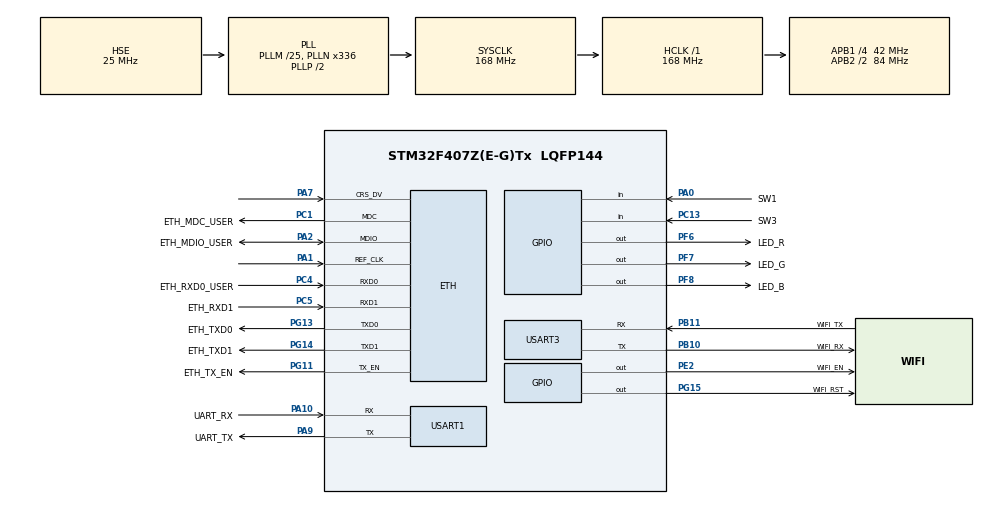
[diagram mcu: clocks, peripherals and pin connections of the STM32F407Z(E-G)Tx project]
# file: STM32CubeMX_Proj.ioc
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Dma.Request0=USART1_TX
Dma.Request1=USART1_RX
Dma.Request2=USART3_RX
Dma.Request3=USART3_TX
Dma.USART1_RX.1.Direction=DMA_PERIPH_TO_MEMORY
Dma.USART1_RX.1.FIFOMode=DMA_FIFOMODE_DISABLE
Dma.USART1_RX.1.Instance=DMA2_Stream2
Dma.USART1_RX.1.MemDataAlignment=DMA_MDATAALIGN_BYTE
Dma.USART1_RX.1.MemInc=DMA_MINC_ENABLE
Dma.USART1_RX.1.Mode=DMA_NORMAL
Dma.USART1_RX.1.PeriphDataAlignment=DMA_PDATAALIGN_BYTE
Dma.USART1_RX.1.PeriphInc=DMA_PINC_DISABLE
Dma.USART1_RX.1.Priority=DMA_PRIORITY_MEDIUM
Dma.USART1_TX.0.Direction=DMA_MEMORY_TO_PERIPH
Dma.USART1_TX.0.FIFOMode=DMA_FIFOMODE_DISABLE
Dma.USART1_TX.0.Instance=DMA2_Stream7
Dma.USART1_TX.0.MemDataAlignment=DMA_MDATAALIGN_BYTE
Dma.USART1_TX.0.MemInc=DMA_MINC_ENABLE
Dma.USART1_TX.0.Mode=DMA_NORMAL
Dma.USART1_TX.0.PeriphDataAlignment=DMA_PDATAALIGN_BYTE
Dma.USART1_TX.0.PeriphInc=DMA_PINC_DISABLE
Dma.USART1_TX.0.Priority=DMA_PRIORITY_MEDIUM
Dma.USART3_RX.2.Direction=DMA_PERIPH_TO_MEMORY
Dma.USART3_RX.2.FIFOMode=DMA_FIFOMODE_DISABLE
Dma.USART3_RX.2.Instance=DMA1_Stream1
Dma.USART3_RX.2.MemDataAlignment=DMA_MDATAALIGN_BYTE
Dma.USART3_RX.2.MemInc=DMA_MINC_ENABLE
Dma.USART3_RX.2.Mode=DMA_NORMAL
Dma.USART3_RX.2.PeriphDataAlignment=DMA_PDATAALIGN_BYTE
Dma.USART3_RX.2.PeriphInc=DMA_PINC_DISABLE
Dma.USART3_RX.2.Priority=DMA_PRIORITY_LOW
Dma.USART3_TX.3.Direction=DMA_MEMORY_TO_PERIPH
Dma.USART3_TX.3.FIFOMode=DMA_FIFOMODE_DISABLE
Dma.USART3_TX.3.Instance=DMA1_Stream3
Dma.USART3_TX.3.MemDataAlignment=DMA_MDATAALIGN_BYTE
Dma.USART3_TX.3.MemInc=DMA_MINC_ENABLE
Dma.USART3_TX.3.Mode=DMA_NORMAL
Dma.USART3_TX.3.PeriphDataAlignment=DMA_PDATAALIGN_BYTE
Dma.USART3_TX.3.PeriphInc=DMA_PINC_DISABLE
Dma.USART3_TX.3.Priority=DMA_PRIORITY_LOW
ETH.MediaInterface=HAL_ETH_RMII_MODE
Mcu.Family=STM32F4
Mcu.Name=STM32F407Z(E-G)Tx
Mcu.Package=LQFP144
NVIC.DMA1_Stream1_IRQn=true\:0\:0\:false\:false\:true\:false\:true\:true
NVIC.DMA1_Stream3_IRQn=true\:0\:0\:false\:false\:true\:false\:true\:true
NVIC.DMA2_Stream2_IRQn=true\:0\:0\:false\:false\:true\:false\:true\:true
NVIC.DMA2_Stream7_IRQn=true\:0\:0\:false\:false\:true\:false\:true\:true
NVIC.PriorityGroup=NVIC_PRIORITYGROUP_4
NVIC.USART1_IRQn=true\:0\:0\:false\:false\:true\:false\:true\:true
NVIC.USART3_IRQn=true\:0\:0\:false\:false\:true\:false\:true\:true
PA0-WKUP.GPIO_Label=SW1
PA0-WKUP.Signal=GPIO_Input
PA1.Mode=RMII
PA1.Signal=ETH_REF_CLK
PA10.GPIO_Label=UART_RX
PA10.Mode=Asynchronous
PA10.Signal=USART1_RX
PA2.GPIO_Label=ETH_MDIO_USER
PA2.Mode=RMII
PA2.Signal=ETH_MDIO
PA7.Mode=RMII
PA7.Signal=ETH_CRS_DV
PA9.GPIO_Label=UART_TX
PA9.Mode=Asynchronous
PA9.Signal=USART1_TX
PB10.GPIO_Label=WIFI_RX
PB10.Mode=Asynchronous
PB10.Signal=USART3_TX
PB11.GPIO_Label=WIFI_TX
PB11.Mode=Asynchronous
PB11.Signal=USART3_RX
PC1.GPIO_Label=ETH_MDC_USER
PC1.Mode=RMII
PC1.Signal=ETH_MDC
PC13-ANTI_TAMP.GPIO_Label=SW3
PC13-ANTI_TAMP.Signal=GPIO_Input
PC4.GPIO_Label=ETH_RXD0_USER
PC4.Mode=RMII
PC4.Signal=ETH_RXD0
PC5.GPIO_Label=ETH_RXD1
PC5.Mode=RMII
PC5.Signal=ETH_RXD1
PE2.GPIO_Label=WIFI_EN
PE2.PinState=GPIO_PIN_RESET
PE2.Signal=GPIO_Output
PF6.GPIO_Label=LED_R
PF6.PinState=GPIO_PIN_SET
PF6.Signal=GPIO_Output
PF7.GPIO_Label=LED_G
PF7.PinState=GPIO_PIN_SET
PF7.Signal=GPIO_Output
PF8.GPIO_Label=LED_B
PF8.PinState=GPIO_PIN_SET
PF8.Signal=GPIO_Output
PG11.GPIO_Label=ETH_TX_EN
PG11.Mode=RMII
PG11.Signal=ETH_TX_EN
PG13.GPIO_Label=ETH_TXD0
PG13.Mode=RMII
PG13.Signal=ETH_TXD0
PG14.GPIO_Label=ETH_TXD1
PG14.Mode=RMII
PG14.Signal=ETH_TXD1
PG15.GPIO_Label=WIFI_RST
PG15.Signal=GPIO_Output
PH0-OSC_IN.Mode=HSE-External-Oscillator
PH0-OSC_IN.Signal=RCC_OSC_IN
PH1-OSC_OUT.Mode=HSE-External-Oscillator
PH1-OSC_OUT.Signal=RCC_OSC_OUT
ProjectManager.HeapSize=0x200
ProjectManager.StackSize=0x400
ProjectManager.TargetToolchain=MDK-ARM V5.32
RCC.48MHZClocksFreq_Value=84000000
RCC.AHBFreq_Value=168000000
RCC.APB1CLKDivider=RCC_HCLK_DIV4
RCC.APB1Freq_Value=42000000
RCC.APB1TimFreq_Value=84000000
RCC.APB2CLKDivider=RCC_HCLK_DIV2
RCC.APB2Freq_Value=84000000
RCC.APB2TimFreq_Value=168000000
RCC.CortexFreq_Value=168000000
RCC.HCLKFreq_Value=168000000
RCC.HSE_VALUE=25000000
RCC.HSI_VALUE=16000000
RCC.LSE_VALUE=32768
RCC.PLLM=25
RCC.PLLN=336
RCC.PLLSourceVirtual=RCC_PLLSOURCE_HSE
RCC.SYSCLKFreq_VALUE=168000000
RCC.SYSCLKSource=RCC_SYSCLKSOURCE_PLLCLK
RCC.VCOOutputFreq_Value=336000000
USART1.VirtualMode=VM_ASYNC
USART3.VirtualMode=VM_ASYNC
board=custom

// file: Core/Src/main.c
/* USER CODE BEGIN Header */
/**
  ******************************************************************************
  * @file           : main.c
  * @brief          : Main program body
  ******************************************************************************
  * @attention
  *
  * Copyright (c) 2026 STMicroelectronics.
  * All rights reserved.
  *
  * This software is licensed under terms that can be found in the LICENSE file
  * in the root directory of this software component.
  * If no LICENSE file comes with this software, it is provided AS-IS.
  *
  ******************************************************************************
  */
/* USER CODE END Header */
#include "main.h"

//ETH_TxPacketConfig TxConfig;
//ETH_DMADescTypeDef  DMARxDscrTab[ETH_RX_DESC_CNT]; /* Ethernet Rx DMA Descriptors */
//ETH_DMADescTypeDef  DMATxDscrTab[ETH_TX_DESC_CNT]; /* Ethernet Tx DMA Descriptors */

//ETH_HandleTypeDef heth;

UART_HandleTypeDef huart1;
UART_HandleTypeDef huart3;
DMA_HandleTypeDef hdma_usart1_tx;
DMA_HandleTypeDef hdma_usart1_rx;
DMA_HandleTypeDef hdma_usart3_rx;
DMA_HandleTypeDef hdma_usart3_tx;

void SystemClock_Config(void);
static void MX_GPIO_Init(void);
static void MX_DMA_Init(void);
static void MX_USART1_UART_Init(void);
static void MX_USART3_UART_Init(void);
//static void MX_ETH_Init(void);

int main(void)
{

  /* MCU Configuration--------------------------------------------------------*/

  /* Reset of all peripherals, Initializes the Flash interface and the Systick. */
  HAL_Init();

  /* Configure the system clock */
  SystemClock_Config();

  /* Initialize all configured peripherals */
  MX_GPIO_Init();
  MX_DMA_Init();
  MX_USART1_UART_Init();
  MX_USART3_UART_Init();
	WIFI_Enable();
	printf("==> BSP初始化成功\n");
  /* USER CODE BEGIN 2 */
	User_Start_Tasks();
  /* USER CODE END 2 */

  /* Infinite loop */
  while (1)
  {

  }
}

void SystemClock_Config(void)
{
  RCC_OscInitTypeDef RCC_OscInitStruct = {0};
  RCC_ClkInitTypeDef RCC_ClkInitStruct = {0};

  /** Configure the main internal regulator output voltage
  */
  __HAL_RCC_PWR_CLK_ENABLE();
  __HAL_PWR_VOLTAGESCALING_CONFIG(PWR_REGULATOR_VOLTAGE_SCALE1);

  /** Initializes the RCC Oscillators according to the specified parameters
  * in the RCC_OscInitTypeDef structure.
  */
  RCC_OscInitStruct.OscillatorType = RCC_OSCILLATORTYPE_HSE;
  RCC_OscInitStruct.HSEState = RCC_HSE_ON;
  RCC_OscInitStruct.PLL.PLLState = RCC_PLL_ON;
  RCC_OscInitStruct.PLL.PLLSource = RCC_PLLSOURCE_HSE;
  RCC_OscInitStruct.PLL.PLLM = 25;
  RCC_OscInitStruct.PLL.PLLN = 336;
  RCC_OscInitStruct.PLL.PLLP = RCC_PLLP_DIV2;
  RCC_OscInitStruct.PLL.PLLQ = 4;
  if (HAL_RCC_OscConfig(&RCC_OscInitStruct) != HAL_OK)
  {
    Error_Handler();
  }

  /** Initializes the CPU, AHB and APB buses clocks
  */
  RCC_ClkInitStruct.ClockType = RCC_CLOCKTYPE_HCLK|RCC_CLOCKTYPE_SYSCLK
                              |RCC_CLOCKTYPE_PCLK1|RCC_CLOCKTYPE_PCLK2;
  RCC_ClkInitStruct.SYSCLKSource = RCC_SYSCLKSOURCE_PLLCLK;
  RCC_ClkInitStruct.AHBCLKDivider = RCC_SYSCLK_DIV1;
  RCC_ClkInitStruct.APB1CLKDivider = RCC_HCLK_DIV4;
  RCC_ClkInitStruct.APB2CLKDivider = RCC_HCLK_DIV2;

  if (HAL_RCC_ClockConfig(&RCC_ClkInitStruct, FLASH_LATENCY_5) != HAL_OK)
  {
    Error_Handler();
  }
}

static void MX_USART1_UART_Init(void)
{

  huart1.Instance = USART1;
  huart1.Init.BaudRate = 115200;
  huart1.Init.WordLength = UART_WORDLENGTH_8B;
  huart1.Init.StopBits = UART_STOPBITS_1;
  huart1.Init.Parity = UART_PARITY_NONE;
  huart1.Init.Mode = UART_MODE_TX_RX;
  huart1.Init.HwFlowCtl = UART_HWCONTROL_NONE;
  huart1.Init.OverSampling = UART_OVERSAMPLING_16;
  if (HAL_UART_Init(&huart1) != HAL_OK)
  {
    Error_Handler();
  }

}

static void MX_USART3_UART_Init(void)
{

  huart3.Instance = USART3;
  huart3.Init.BaudRate = 115200;
  huart3.Init.WordLength = UART_WORDLENGTH_8B;
  huart3.Init.StopBits = UART_STOPBITS_1;
  huart3.Init.Parity = UART_PARITY_NONE;
  huart3.Init.Mode = UART_MODE_TX_RX;
  huart3.Init.HwFlowCtl = UART_HWCONTROL_NONE;
  huart3.Init.OverSampling = UART_OVERSAMPLING_16;
  if (HAL_UART_Init(&huart3) != HAL_OK)
  {
    Error_Handler();
  }

}

static void MX_DMA_Init(void)
{

  /* DMA controller clock enable */
  __HAL_RCC_DMA2_CLK_ENABLE();
  __HAL_RCC_DMA1_CLK_ENABLE();

  /* DMA interrupt init */
  /* DMA1_Stream1_IRQn interrupt configuration */
  HAL_NVIC_SetPriority(DMA1_Stream1_IRQn, 0, 0);
  HAL_NVIC_EnableIRQ(DMA1_Stream1_IRQn);
  /* DMA1_Stream3_IRQn interrupt configuration */
  HAL_NVIC_SetPriority(DMA1_Stream3_IRQn, 0, 0);
  HAL_NVIC_EnableIRQ(DMA1_Stream3_IRQn);
  /* DMA2_Stream2_IRQn interrupt configuration */
  HAL_NVIC_SetPriority(DMA2_Stream2_IRQn, 0, 0);
  HAL_NVIC_EnableIRQ(DMA2_Stream2_IRQn);
  /* DMA2_Stream7_IRQn interrupt configuration */
  HAL_NVIC_SetPriority(DMA2_Stream7_IRQn, 0, 0);
  HAL_NVIC_EnableIRQ(DMA2_Stream7_IRQn);

}

static void MX_GPIO_Init(void)
{
  GPIO_InitTypeDef GPIO_InitStruct = {0};

  /* GPIO Ports Clock Enable */
  __HAL_RCC_GPIOE_CLK_ENABLE();
  __HAL_RCC_GPIOC_CLK_ENABLE();
  __HAL_RCC_GPIOF_CLK_ENABLE();
  __HAL_RCC_GPIOH_CLK_ENABLE();
  __HAL_RCC_GPIOA_CLK_ENABLE();
  __HAL_RCC_GPIOB_CLK_ENABLE();
  __HAL_RCC_GPIOG_CLK_ENABLE();
  __HAL_RCC_GPIOI_CLK_ENABLE();

  /*Configure GPIO pin Output Level */
  HAL_GPIO_WritePin(WIFI_EN_GPIO_Port, WIFI_EN_Pin, GPIO_PIN_RESET);

  /*Configure GPIO pin Output Level */
  HAL_GPIO_WritePin(GPIOF, LED_R_Pin|LED_G_Pin|LED_B_Pin, GPIO_PIN_SET);

  /*Configure GPIO pin Output Level */
  HAL_GPIO_WritePin(WIFI_RST_GPIO_Port, WIFI_RST_Pin, GPIO_PIN_RESET);

  /*Configure GPIO pin : WIFI_EN_Pin */
  GPIO_InitStruct.Pin = WIFI_EN_Pin;
  GPIO_InitStruct.Mode = GPIO_MODE_OUTPUT_PP;
  GPIO_InitStruct.Pull = GPIO_NOPULL;
  GPIO_InitStruct.Speed = GPIO_SPEED_FREQ_LOW;
  HAL_GPIO_Init(WIFI_EN_GPIO_Port, &GPIO_InitStruct);

  /*Configure GPIO pin : SW3_Pin */
  GPIO_InitStruct.Pin = SW3_Pin;
  GPIO_InitStruct.Mode = GPIO_MODE_INPUT;
  GPIO_InitStruct.Pull = GPIO_NOPULL;
  HAL_GPIO_Init(SW3_GPIO_Port, &GPIO_InitStruct);

  /*Configure GPIO pins : LED_R_Pin LED_G_Pin LED_B_Pin */
  GPIO_InitStruct.Pin = LED_R_Pin|LED_G_Pin|LED_B_Pin;
  GPIO_InitStruct.Mode = GPIO_MODE_OUTPUT_PP;
  GPIO_InitStruct.Pull = GPIO_NOPULL;
  GPIO_InitStruct.Speed = GPIO_SPEED_FREQ_LOW;
  HAL_GPIO_Init(GPIOF, &GPIO_InitStruct);

  /*Configure GPIO pin : SW1_Pin */
  GPIO_InitStruct.Pin = SW1_Pin;
  GPIO_InitStruct.Mode = GPIO_MODE_INPUT;
  GPIO_InitStruct.Pull = GPIO_NOPULL;
  HAL_GPIO_Init(SW1_GPIO_Port, &GPIO_InitStruct);

  /*Configure GPIO pin : WIFI_RST_Pin */
  GPIO_InitStruct.Pin = WIFI_RST_Pin;
  GPIO_InitStruct.Mode = GPIO_MODE_OUTPUT_PP;
  GPIO_InitStruct.Pull = GPIO_NOPULL;
  GPIO_InitStruct.Speed = GPIO_SPEED_FREQ_LOW;
  HAL_GPIO_Init(WIFI_RST_GPIO_Port, &GPIO_InitStruct);

}

void Error_Handler(void)
{
  __disable_irq();
  while (1)
  {
  }
}
